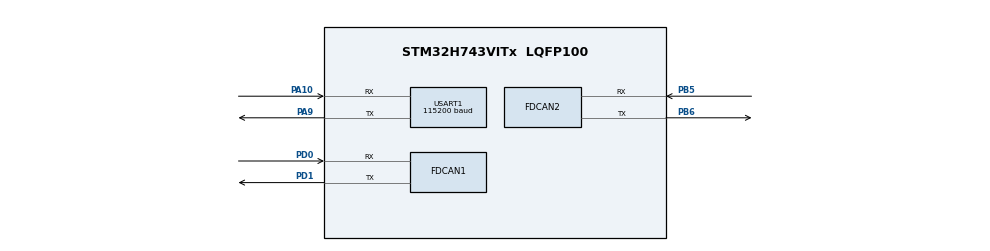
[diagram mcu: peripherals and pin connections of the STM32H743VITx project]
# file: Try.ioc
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Dma.Request0=USART1_RX
Dma.Request1=USART1_TX
Dma.USART1_RX.0.Direction=DMA_PERIPH_TO_MEMORY
Dma.USART1_RX.0.EventEnable=DISABLE
Dma.USART1_RX.0.FIFOMode=DMA_FIFOMODE_DISABLE
Dma.USART1_RX.0.Instance=DMA1_Stream0
Dma.USART1_RX.0.MemDataAlignment=DMA_MDATAALIGN_BYTE
Dma.USART1_RX.0.MemInc=DMA_MINC_ENABLE
Dma.USART1_RX.0.Mode=DMA_NORMAL
Dma.USART1_RX.0.PeriphDataAlignment=DMA_PDATAALIGN_BYTE
Dma.USART1_RX.0.PeriphInc=DMA_PINC_DISABLE
Dma.USART1_RX.0.Polarity=HAL_DMAMUX_REQ_GEN_RISING
Dma.USART1_RX.0.Priority=DMA_PRIORITY_VERY_HIGH
Dma.USART1_RX.0.RequestNumber=1
Dma.USART1_RX.0.SignalID=NONE
Dma.USART1_RX.0.SyncEnable=DISABLE
Dma.USART1_RX.0.SyncPolarity=HAL_DMAMUX_SYNC_NO_EVENT
Dma.USART1_RX.0.SyncRequestNumber=1
Dma.USART1_RX.0.SyncSignalID=NONE
Dma.USART1_TX.1.Direction=DMA_MEMORY_TO_PERIPH
Dma.USART1_TX.1.EventEnable=DISABLE
Dma.USART1_TX.1.FIFOMode=DMA_FIFOMODE_DISABLE
Dma.USART1_TX.1.Instance=DMA1_Stream1
Dma.USART1_TX.1.MemDataAlignment=DMA_MDATAALIGN_BYTE
Dma.USART1_TX.1.MemInc=DMA_MINC_ENABLE
Dma.USART1_TX.1.Mode=DMA_CIRCULAR
Dma.USART1_TX.1.PeriphDataAlignment=DMA_PDATAALIGN_BYTE
Dma.USART1_TX.1.PeriphInc=DMA_PINC_DISABLE
Dma.USART1_TX.1.Polarity=HAL_DMAMUX_REQ_GEN_RISING
Dma.USART1_TX.1.Priority=DMA_PRIORITY_HIGH
Dma.USART1_TX.1.RequestNumber=1
Dma.USART1_TX.1.SignalID=NONE
Dma.USART1_TX.1.SyncEnable=DISABLE
Dma.USART1_TX.1.SyncPolarity=HAL_DMAMUX_SYNC_NO_EVENT
Dma.USART1_TX.1.SyncRequestNumber=1
Dma.USART1_TX.1.SyncSignalID=NONE
FDCAN1.AutoRetransmission=ENABLE
FDCAN1.CalculateBaudRateNominal=1000000
FDCAN1.CalculateTimeBitNominal=1000
FDCAN1.CalculateTimeQuantumNominal=25.0
FDCAN1.DataPrescaler=3
FDCAN1.DataSyncJumpWidth=10
FDCAN1.DataTimeSeg1=29
FDCAN1.DataTimeSeg2=10
FDCAN1.NominalPrescaler=3
FDCAN1.NominalSyncJumpWidth=10
FDCAN1.NominalTimeSeg1=29
FDCAN1.NominalTimeSeg2=10
FDCAN1.ProtocolException=ENABLE
FDCAN1.RxFifo0ElmtsNbr=4
FDCAN1.RxFifo1ElmtsNbr=4
FDCAN1.StdFiltersNbr=1
FDCAN1.TxFifoQueueElmtsNbr=4
FDCAN2.AutoRetransmission=ENABLE
FDCAN2.CalculateBaudRateNominal=1000000
FDCAN2.CalculateTimeBitNominal=1000
FDCAN2.CalculateTimeQuantumNominal=25.0
FDCAN2.DataPrescaler=3
FDCAN2.DataSyncJumpWidth=10
FDCAN2.DataTimeSeg1=29
FDCAN2.DataTimeSeg2=10
FDCAN2.MessageRAMOffset=1280
FDCAN2.NominalPrescaler=3
FDCAN2.NominalSyncJumpWidth=10
FDCAN2.NominalTimeSeg1=29
FDCAN2.NominalTimeSeg2=10
FDCAN2.ProtocolException=ENABLE
FDCAN2.RxFifo0ElmtsNbr=4
FDCAN2.StdFiltersNbr=1
FDCAN2.TxFifoQueueElmtsNbr=4
FREERTOS.INCLUDE_vTaskDelayUntil=1
FREERTOS.Tasks01=defaultTask,0,128,StartDefaultTask,Default,NULL,Dynamic,NULL,NULL
Mcu.Family=STM32H7
Mcu.Name=STM32H743VITx
Mcu.Package=LQFP100
NVIC.DMA1_Stream0_IRQn=true\:5\:0\:false\:false\:true\:true\:false\:true\:true
NVIC.DMA1_Stream1_IRQn=true\:5\:0\:false\:false\:true\:true\:false\:true\:true
NVIC.FDCAN1_IT0_IRQn=true\:5\:0\:false\:false\:true\:true\:true\:true\:true
NVIC.FDCAN1_IT1_IRQn=true\:5\:0\:false\:false\:true\:true\:true\:true\:true
NVIC.FDCAN2_IT0_IRQn=true\:5\:0\:false\:false\:true\:true\:true\:true\:true
NVIC.FDCAN2_IT1_IRQn=true\:5\:0\:false\:false\:true\:true\:true\:true\:true
NVIC.PriorityGroup=NVIC_PRIORITYGROUP_4
NVIC.TIM6_DAC_IRQn=true\:15\:0\:false\:false\:true\:false\:false\:true\:true
NVIC.TimeBase=TIM6_DAC_IRQn
NVIC.TimeBaseIP=TIM6
NVIC.USART1_IRQn=true\:5\:0\:false\:false\:true\:true\:true\:true\:true
PA10.Mode=Asynchronous
PA10.Signal=USART1_RX
PA9.Mode=Asynchronous
PA9.Signal=USART1_TX
PB5.Mode=FDCAN_Activate
PB5.Signal=FDCAN2_RX
PB6.Mode=FDCAN_Activate
PB6.Signal=FDCAN2_TX
PD0.Mode=FDCAN_Activate
PD0.Signal=FDCAN1_RX
PD1.Mode=FDCAN_Activate
PD1.Signal=FDCAN1_TX
PH0-OSC_IN\ (PH0).Mode=HSE-External-Oscillator
PH0-OSC_IN\ (PH0).Signal=RCC_OSC_IN
PH1-OSC_OUT\ (PH1).Mode=HSE-External-Oscillator
PH1-OSC_OUT\ (PH1).Signal=RCC_OSC_OUT
ProjectManager.HeapSize=0x200
ProjectManager.StackSize=0x400
ProjectManager.TargetToolchain=MDK-ARM V5.32
RCC.ADCFreq_Value=24187500
RCC.APB1Freq_Value=120000000
RCC.APB2Freq_Value=120000000
RCC.APB3Freq_Value=120000000
RCC.APB4Freq_Value=120000000
RCC.CortexFreq_Value=480000000
RCC.D1PPRE=RCC_APB3_DIV2
RCC.D2PPRE1=RCC_APB1_DIV2
RCC.D2PPRE2=RCC_APB2_DIV2
RCC.D3PPRE=RCC_APB4_DIV2
RCC.DIVM1=1
RCC.DIVN1=80
RCC.DIVQ1=8
RCC.HCLKFreq_Value=240000000
RCC.HPRE=RCC_HCLK_DIV2
RCC.HSE_VALUE=12000000
RCC.PLLFRACN=0
RCC.PLLSourceVirtual=RCC_PLLSOURCE_HSE
RCC.SYSCLKFreq_VALUE=480000000
RCC.SYSCLKSource=RCC_SYSCLKSOURCE_PLLCLK
RCC.USBFreq_Value=120000000
USART1.BaudRate=115200
USART1.VirtualMode-Asynchronous=VM_ASYNC
USART1.WordLength=WORDLENGTH_8B
VP_FREERTOS_VS_CMSIS_V1.Mode=CMSIS_V1
VP_MEMORYMAP_VS_MEMORYMAP.Mode=CurAppReg
VP_SYS_VS_tim6.Mode=TIM6
board=custom

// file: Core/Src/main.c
/* USER CODE BEGIN Header */
/**
  ******************************************************************************
  * @file           : main.c
  * @brief          : Main program body
  ******************************************************************************
  * @attention
  *
  * Copyright (c) 2025 STMicroelectronics.
  * All rights reserved.
  *
  * This software is licensed under terms that can be found in the LICENSE file
  * in the root directory of this software component.
  * If no LICENSE file comes with this software, it is provided AS-IS.
  *
  ******************************************************************************
  */
/* USER CODE END Header */
#include "main.h"
#include "cmsis_os.h"
#include "dma.h"
#include "fdcan.h"
#include "memorymap.h"
#include "usart.h"
#include "gpio.h"

/* USER CODE BEGIN Includes */
#include "Arm_Control.h"
#include "bsp_fdcan.h"
#include "bsp_usart.h"
/* USER CODE END Includes */

void SystemClock_Config(void);
void MX_FREERTOS_Init(void);

int main(void)
{

    /* MCU Configuration--------------------------------------------------------*/

    /* Reset of all peripherals, Initializes the Flash interface and the Systick. */
    HAL_Init();

    /* Configure the system clock */
    SystemClock_Config();

    /* Initialize all configured peripherals */
    MX_GPIO_Init();
    MX_DMA_Init();
    MX_FDCAN1_Init();
    MX_FDCAN2_Init();
    MX_USART1_UART_Init();
    /* USER CODE BEGIN 2 */
//	  dm_motor_init();
//    dm_motor_enable(&hfdcan2, &motor[Motor1]);
//	  osDelay(10);
//    dm_motor_enable(&hfdcan2, &motor[Motor2]);
//	  osDelay(10);
//    dm_motor_enable(&hfdcan2, &motor[Motor3]);
//	  osDelay(10);
    bsp_can_init();
    //osDelay(10);
    arm_init();
    // osDelay(10);
    HAL_UARTEx_ReceiveToIdle_DMA(&huart1,rx_buffer,RX_BUFFER_SIZE);

    /* USER CODE END 2 */

    /* Call init function for freertos objects (in cmsis_os2.c) */
    MX_FREERTOS_Init();

    /* Start scheduler */
    osKernelStart();

    /* We should never get here as control is now taken by the scheduler */

    /* Infinite loop */
    while (1)
    {

    }
}

void SystemClock_Config(void)
{
    RCC_OscInitTypeDef RCC_OscInitStruct = {0};
    RCC_ClkInitTypeDef RCC_ClkInitStruct = {0};

    /** Supply configuration update enable
    */
    HAL_PWREx_ConfigSupply(PWR_LDO_SUPPLY);

    /** Configure the main internal regulator output voltage
    */
    __HAL_PWR_VOLTAGESCALING_CONFIG(PWR_REGULATOR_VOLTAGE_SCALE0);

    while(!__HAL_PWR_GET_FLAG(PWR_FLAG_VOSRDY)) {}

    /** Initializes the RCC Oscillators according to the specified parameters
    * in the RCC_OscInitTypeDef structure.
    */
    RCC_OscInitStruct.OscillatorType = RCC_OSCILLATORTYPE_HSE;
    RCC_OscInitStruct.HSEState = RCC_HSE_ON;
    RCC_OscInitStruct.PLL.PLLState = RCC_PLL_ON;
    RCC_OscInitStruct.PLL.PLLSource = RCC_PLLSOURCE_HSE;
    RCC_OscInitStruct.PLL.PLLM = 1;
    RCC_OscInitStruct.PLL.PLLN = 80;
    RCC_OscInitStruct.PLL.PLLP = 2;
    RCC_OscInitStruct.PLL.PLLQ = 8;
    RCC_OscInitStruct.PLL.PLLR = 2;
    RCC_OscInitStruct.PLL.PLLRGE = RCC_PLL1VCIRANGE_3;
    RCC_OscInitStruct.PLL.PLLVCOSEL = RCC_PLL1VCOWIDE;
    RCC_OscInitStruct.PLL.PLLFRACN = 0;
    if (HAL_RCC_OscConfig(&RCC_OscInitStruct) != HAL_OK)
    {
        Error_Handler();
    }

    /** Initializes the CPU, AHB and APB buses clocks
    */
    RCC_ClkInitStruct.ClockType = RCC_CLOCKTYPE_HCLK|RCC_CLOCKTYPE_SYSCLK
                                  |RCC_CLOCKTYPE_PCLK1|RCC_CLOCKTYPE_PCLK2
                                  |RCC_CLOCKTYPE_D3PCLK1|RCC_CLOCKTYPE_D1PCLK1;
    RCC_ClkInitStruct.SYSCLKSource = RCC_SYSCLKSOURCE_PLLCLK;
    RCC_ClkInitStruct.SYSCLKDivider = RCC_SYSCLK_DIV1;
    RCC_ClkInitStruct.AHBCLKDivider = RCC_HCLK_DIV2;
    RCC_ClkInitStruct.APB3CLKDivider = RCC_APB3_DIV2;
    RCC_ClkInitStruct.APB1CLKDivider = RCC_APB1_DIV2;
    RCC_ClkInitStruct.APB2CLKDivider = RCC_APB2_DIV2;
    RCC_ClkInitStruct.APB4CLKDivider = RCC_APB4_DIV2;

    if (HAL_RCC_ClockConfig(&RCC_ClkInitStruct, FLASH_LATENCY_4) != HAL_OK)
    {
        Error_Handler();
    }
}

void HAL_TIM_PeriodElapsedCallback(TIM_HandleTypeDef *htim)
{
    if (htim->Instance == TIM6) {
        HAL_IncTick();
    }
}

void Error_Handler(void)
{
    __disable_irq();
    while (1)
    {
    }
}

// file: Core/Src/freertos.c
/* USER CODE BEGIN Header */
/**
  ******************************************************************************
  * File Name          : freertos.c
  * Description        : Code for freertos applications
  ******************************************************************************
  * @attention
  *
  * Copyright (c) 2025 STMicroelectronics.
  * All rights reserved.
  *
  * This software is licensed under terms that can be found in the LICENSE file
  * in the root directory of this software component.
  * If no LICENSE file comes with this software, it is provided AS-IS.
  *
  ******************************************************************************
  */
/* USER CODE END Header */

#include "FreeRTOS.h"
#include "task.h"
#include "main.h"
#include "cmsis_os.h"

/* USER CODE BEGIN Includes */
#include "bsp_fdcan.h"
#include "Task_Arm.h"
#include "bsp_usart.h"

/* USER CODE END Includes */

/* USER CODE BEGIN PM */
osThreadId Arm_Control_Handle;
/* USER CODE END PM */

osThreadId defaultTaskHandle;

/* USER CODE BEGIN FunctionPrototypes */
extern void arm_control(void const *argument);

/* USER CODE END FunctionPrototypes */

void StartDefaultTask(void const * argument);

void MX_FREERTOS_Init(void); /* (MISRA C 2004 rule 8.1) */

/* GetIdleTaskMemory prototype (linked to static allocation support) */
void vApplicationGetIdleTaskMemory( StaticTask_t **ppxIdleTaskTCBBuffer, StackType_t **ppxIdleTaskStackBuffer, uint32_t *pulIdleTaskStackSize );

/* USER CODE BEGIN GET_IDLE_TASK_MEMORY */
static StaticTask_t xIdleTaskTCBBuffer;
static StackType_t xIdleStack[configMINIMAL_STACK_SIZE];

void vApplicationGetIdleTaskMemory( StaticTask_t **ppxIdleTaskTCBBuffer, StackType_t **ppxIdleTaskStackBuffer, uint32_t *pulIdleTaskStackSize )
{
  *ppxIdleTaskTCBBuffer = &xIdleTaskTCBBuffer;
  *ppxIdleTaskStackBuffer = &xIdleStack[0];
  *pulIdleTaskStackSize = configMINIMAL_STACK_SIZE;
  /* place for user code */
}
/* USER CODE END GET_IDLE_TASK_MEMORY */

void MX_FREERTOS_Init(void) {

  /* Create the thread(s) */
  /* definition and creation of defaultTask */
  osThreadDef(defaultTask, StartDefaultTask, osPriorityNormal, 0, 128);
  defaultTaskHandle = osThreadCreate(osThread(defaultTask), NULL);

  /* USER CODE BEGIN RTOS_THREADS */

	osThreadDef(Arm_Control_Task, Arm_Control, osPriorityHigh, 0, 1024);
	Arm_Control_Handle = osThreadCreate(osThread(Arm_Control_Task), NULL);
  /* add threads, ... */
  /* USER CODE END RTOS_THREADS */

}

void StartDefaultTask(void const * argument)
{
  for(;;)
  {
  }
}
